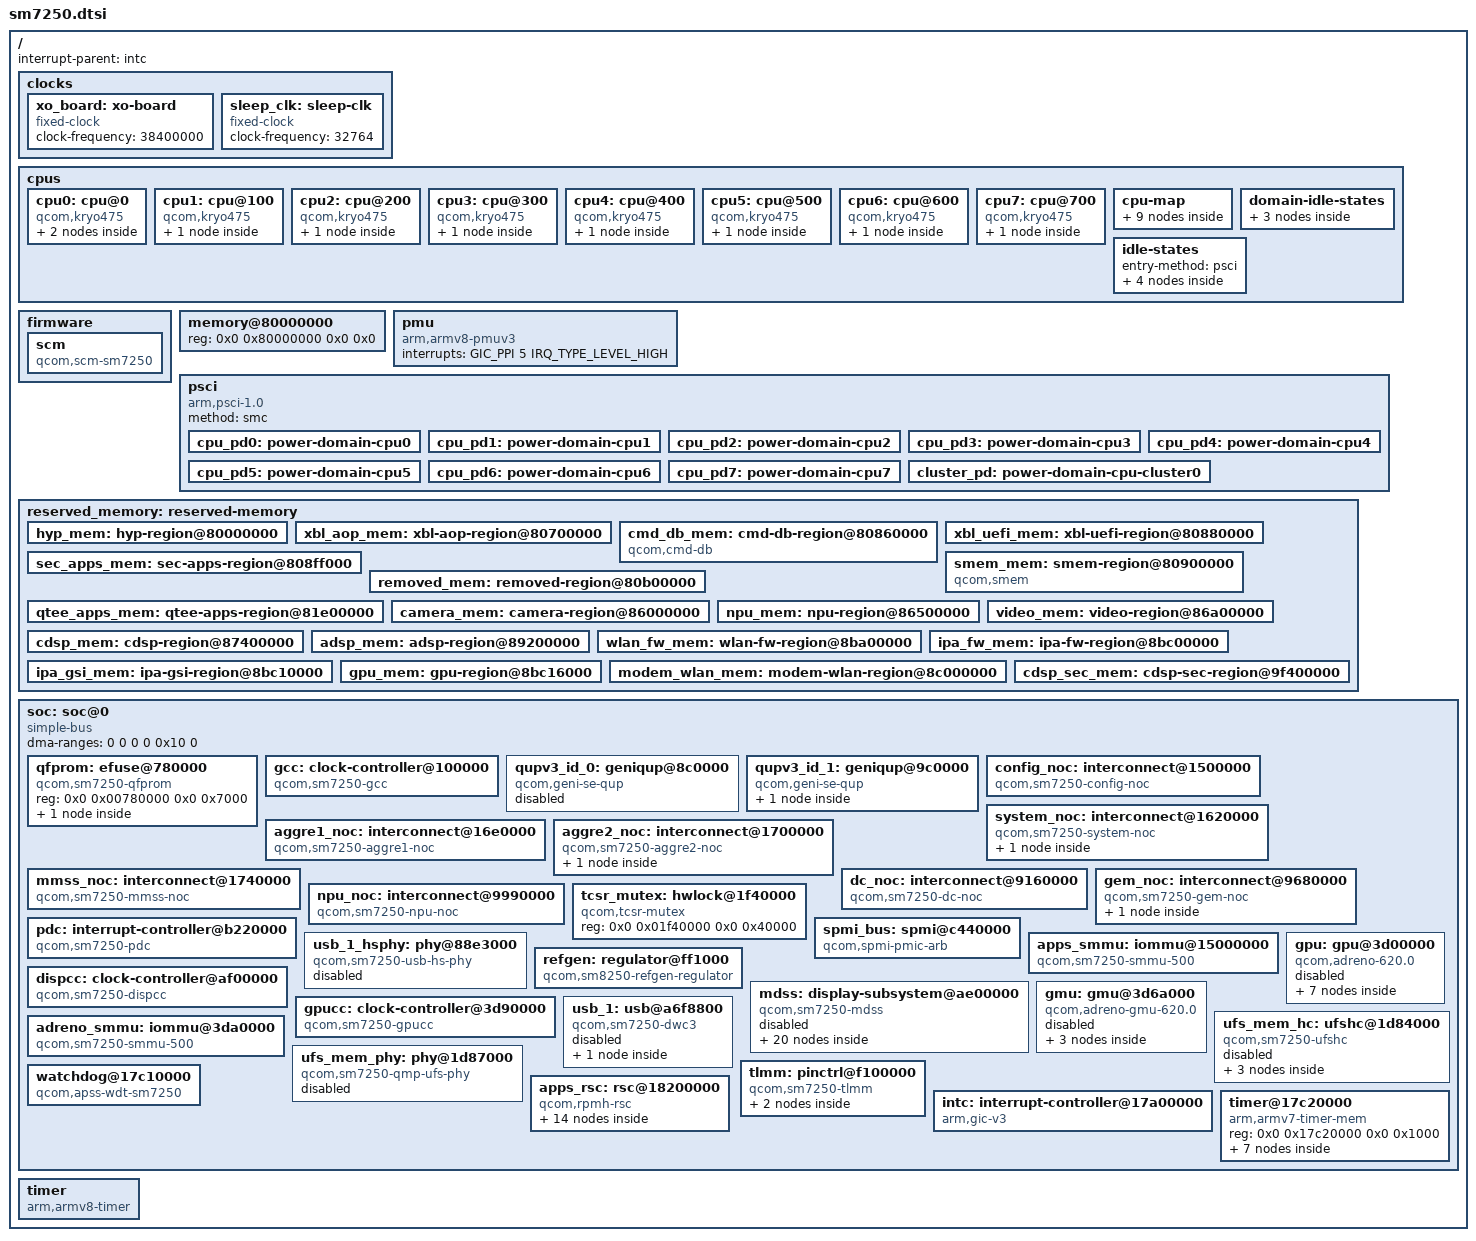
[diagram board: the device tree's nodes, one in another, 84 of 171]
// SPDX-License-Identifier: BSD-3-Clause
/*
 * Copyright (c) 2026, Sreeshankar K <sreeshankar0910@gmail.com>
 *
 * Based on the SM7250 base devicetree posted in the v14 series. The cpufreq
 * and LMH nodes are omitted until their dependencies are in the tree.
 */

#include <dt-bindings/clock/qcom,rpmh.h>
#include <dt-bindings/clock/qcom,sm7250-gcc.h>
#include <dt-bindings/clock/qcom,sm7250-dispcc.h>
#include <dt-bindings/clock/qcom,gpucc-sm7250.h>
#include <dt-bindings/clock/qcom,dsi-phy-28nm.h>
#include <dt-bindings/interconnect/qcom,icc.h>
#include <dt-bindings/interconnect/qcom,sm7250-rpmh.h>
#include <dt-bindings/interrupt-controller/arm-gic.h>
#include <dt-bindings/regulator/qcom,rpmh-regulator.h>
#include <dt-bindings/power/qcom,rpmhpd.h>
#include <dt-bindings/soc/qcom,rpmh-rsc.h>

/ {
	interrupt-parent = <&intc>;
	#address-cells = <2>;
	#size-cells = <2>;

	clocks {
		xo_board: xo-board {
			compatible = "fixed-clock";
			clock-frequency = <38400000>;
			#clock-cells = <0>;
		};

		sleep_clk: sleep-clk {
			compatible = "fixed-clock";
			clock-frequency = <32764>;
			#clock-cells = <0>;
		};
	};

	cpus {
		#address-cells = <2>;
		#size-cells = <0>;

		cpu0: cpu@0 {
			device_type = "cpu";
			compatible = "qcom,kryo475";
			reg = <0x0 0x0>;
			enable-method = "psci";
			capacity-dmips-mhz = <1024>;
			dynamic-power-coefficient = <100>;
			next-level-cache = <&l2_0>;
			power-domains = <&cpu_pd0>;
			power-domain-names = "psci";
			#cooling-cells = <2>;

			l2_0: l2-cache {
				compatible = "cache";
				cache-level = <2>;
				cache-size = <0x20000>;
				cache-unified;
				next-level-cache = <&l3_0>;

				l3_0: l3-cache {
					compatible = "cache";
					cache-level = <3>;
					cache-size = <0x200000>;
					cache-unified;
				};
			};
		};

		cpu1: cpu@100 {
			device_type = "cpu";
			compatible = "qcom,kryo475";
			reg = <0x0 0x100>;
			enable-method = "psci";
			capacity-dmips-mhz = <1024>;
			dynamic-power-coefficient = <100>;
			next-level-cache = <&l2_100>;
			power-domains = <&cpu_pd1>;
			power-domain-names = "psci";
			#cooling-cells = <2>;

			l2_100: l2-cache {
				compatible = "cache";
				cache-level = <2>;
				cache-size = <0x20000>;
				cache-unified;
				next-level-cache = <&l3_0>;
			};
		};

		cpu2: cpu@200 {
			device_type = "cpu";
			compatible = "qcom,kryo475";
			reg = <0x0 0x200>;
			enable-method = "psci";
			capacity-dmips-mhz = <1024>;
			dynamic-power-coefficient = <100>;
			next-level-cache = <&l2_200>;
			power-domains = <&cpu_pd2>;
			power-domain-names = "psci";
			#cooling-cells = <2>;

			l2_200: l2-cache {
				compatible = "cache";
				cache-level = <2>;
				cache-size = <0x20000>;
				cache-unified;
				next-level-cache = <&l3_0>;
			};
		};

		cpu3: cpu@300 {
			device_type = "cpu";
			compatible = "qcom,kryo475";
			reg = <0x0 0x300>;
			enable-method = "psci";
			capacity-dmips-mhz = <1024>;
			dynamic-power-coefficient = <100>;
			next-level-cache = <&l2_300>;
			power-domains = <&cpu_pd3>;
			power-domain-names = "psci";
			#cooling-cells = <2>;

			l2_300: l2-cache {
				compatible = "cache";
				cache-level = <2>;
				cache-size = <0x20000>;
				cache-unified;
				next-level-cache = <&l3_0>;
			};
		};

		cpu4: cpu@400 {
			device_type = "cpu";
			compatible = "qcom,kryo475";
			reg = <0x0 0x400>;
			enable-method = "psci";
			capacity-dmips-mhz = <1024>;
			dynamic-power-coefficient = <100>;
			next-level-cache = <&l2_400>;
			power-domains = <&cpu_pd4>;
			power-domain-names = "psci";
			#cooling-cells = <2>;

			l2_400: l2-cache {
				compatible = "cache";
				cache-level = <2>;
				cache-size = <0x20000>;
				cache-unified;
				next-level-cache = <&l3_0>;
			};
		};

		cpu5: cpu@500 {
			device_type = "cpu";
			compatible = "qcom,kryo475";
			reg = <0x0 0x500>;
			enable-method = "psci";
			capacity-dmips-mhz = <1024>;
			dynamic-power-coefficient = <100>;
			next-level-cache = <&l2_500>;
			power-domains = <&cpu_pd5>;
			power-domain-names = "psci";
			#cooling-cells = <2>;

			l2_500: l2-cache {
				compatible = "cache";
				cache-level = <2>;
				cache-size = <0x20000>;
				cache-unified;
				next-level-cache = <&l3_0>;
			};
		};

		cpu6: cpu@600 {
			device_type = "cpu";
			compatible = "qcom,kryo475";
			reg = <0x0 0x600>;
			enable-method = "psci";
			capacity-dmips-mhz = <1740>;
			dynamic-power-coefficient = <341>;
			next-level-cache = <&l2_600>;
			power-domains = <&cpu_pd6>;
			power-domain-names = "psci";
			#cooling-cells = <2>;

			l2_600: l2-cache {
				compatible = "cache";
				cache-level = <2>;
				cache-size = <0x40000>;
				cache-unified;
				next-level-cache = <&l3_0>;
			};
		};

		cpu7: cpu@700 {
			device_type = "cpu";
			compatible = "qcom,kryo475";
			reg = <0x0 0x700>;
			enable-method = "psci";
			capacity-dmips-mhz = <1740>;
			dynamic-power-coefficient = <375>;
			next-level-cache = <&l2_700>;
			power-domains = <&cpu_pd7>;
			power-domain-names = "psci";
			#cooling-cells = <2>;

			l2_700: l2-cache {
				compatible = "cache";
				cache-level = <2>;
				cache-size = <0x80000>;
				cache-unified;
				next-level-cache = <&l3_0>;
			};
		};

		cpu-map {
			cluster0 {
				core0 {
					cpu = <&cpu0>;
				};

				core1 {
					cpu = <&cpu1>;
				};

				core2 {
					cpu = <&cpu2>;
				};

				core3 {
					cpu = <&cpu3>;
				};

				core4 {
					cpu = <&cpu4>;
				};

				core5 {
					cpu = <&cpu5>;
				};

				core6 {
					cpu = <&cpu6>;
				};

				core7 {
					cpu = <&cpu7>;
				};
			};
		};

		domain-idle-states {
			cluster_sleep_pc: cluster-sleep-0 {
				compatible = "domain-idle-state";
				arm,psci-suspend-param = <0x41000044>;
				entry-latency-us = <2752>;
				exit-latency-us = <3048>;
				min-residency-us = <6118>;
			};

			cluster_sleep_cx: cluster-sleep-1 {
				compatible = "domain-idle-state";
				arm,psci-suspend-param = <0x41002244>;
				entry-latency-us = <3638>;
				exit-latency-us = <4562>;
				min-residency-us = <8467>;
			};

			cluster_sleep_aoss: cluster-sleep-2 {
				compatible = "domain-idle-state";
				arm,psci-suspend-param = <0x4100c244>;
				entry-latency-us = <3263>;
				exit-latency-us = <6562>;
				min-residency-us = <9826>;
			};
		};

		idle-states {
			entry-method = "psci";

			little_cpu_sleep_0: cpu-sleep-0-0 {
				compatible = "arm,idle-state";
				idle-state-name = "little-power-collapse";
				arm,psci-suspend-param = <0x40000003>;
				entry-latency-us = <549>;
				exit-latency-us = <901>;
				min-residency-us = <1774>;
				local-timer-stop;
			};

			little_cpu_sleep_1: cpu-sleep-0-1 {
				compatible = "arm,idle-state";
				idle-state-name = "little-rail-power-collapse";
				arm,psci-suspend-param = <0x40000004>;
				entry-latency-us = <702>;
				exit-latency-us = <915>;
				min-residency-us = <4001>;
				local-timer-stop;
			};

			big_cpu_sleep_0: cpu-sleep-1-0 {
				compatible = "arm,idle-state";
				idle-state-name = "big-power-collapse";
				arm,psci-suspend-param = <0x40000003>;
				entry-latency-us = <523>;
				exit-latency-us = <1244>;
				min-residency-us = <2207>;
				local-timer-stop;
			};

			big_cpu_sleep_1: cpu-sleep-1-1 {
				compatible = "arm,idle-state";
				idle-state-name = "big-rail-power-collapse";
				arm,psci-suspend-param = <0x40000004>;
				entry-latency-us = <526>;
				exit-latency-us = <1854>;
				min-residency-us = <5555>;
				local-timer-stop;
			};
		};
	};

	firmware {
		scm: scm {
			compatible = "qcom,scm-sm7250", "qcom,scm";
			#reset-cells = <1>;
		};
	};

	memory@80000000 {
		device_type = "memory";
		/* We expect the bootloader to fill in the size */
		reg = <0x0 0x80000000 0x0 0x0>;
	};

	pmu {
		compatible = "arm,armv8-pmuv3";
		interrupts = <GIC_PPI 5 IRQ_TYPE_LEVEL_HIGH>;
	};

	psci {
		compatible = "arm,psci-1.0";
		method = "smc";

		cpu_pd0: power-domain-cpu0 {
			#power-domain-cells = <0>;
			power-domains = <&cluster_pd>;
			domain-idle-states = <&little_cpu_sleep_0>,
					     <&little_cpu_sleep_1>;
		};

		cpu_pd1: power-domain-cpu1 {
			#power-domain-cells = <0>;
			power-domains = <&cluster_pd>;
			domain-idle-states = <&little_cpu_sleep_0>,
					     <&little_cpu_sleep_1>;
		};

		cpu_pd2: power-domain-cpu2 {
			#power-domain-cells = <0>;
			power-domains = <&cluster_pd>;
			domain-idle-states = <&little_cpu_sleep_0>,
					     <&little_cpu_sleep_1>;
		};

		cpu_pd3: power-domain-cpu3 {
			#power-domain-cells = <0>;
			power-domains = <&cluster_pd>;
			domain-idle-states = <&little_cpu_sleep_0>,
					     <&little_cpu_sleep_1>;
		};

		cpu_pd4: power-domain-cpu4 {
			#power-domain-cells = <0>;
			power-domains = <&cluster_pd>;
			domain-idle-states = <&little_cpu_sleep_0>,
					     <&little_cpu_sleep_1>;
		};

		cpu_pd5: power-domain-cpu5 {
			#power-domain-cells = <0>;
			power-domains = <&cluster_pd>;
			domain-idle-states = <&little_cpu_sleep_0>,
					     <&little_cpu_sleep_1>;
		};

		cpu_pd6: power-domain-cpu6 {
			#power-domain-cells = <0>;
			power-domains = <&cluster_pd>;
			domain-idle-states = <&big_cpu_sleep_0>,
					     <&big_cpu_sleep_1>;
		};

		cpu_pd7: power-domain-cpu7 {
			#power-domain-cells = <0>;
			power-domains = <&cluster_pd>;
			domain-idle-states = <&big_cpu_sleep_0>,
					     <&big_cpu_sleep_1>;
		};

		cluster_pd: power-domain-cpu-cluster0 {
			#power-domain-cells = <0>;
			domain-idle-states = <&cluster_sleep_pc>,
					     <&cluster_sleep_cx>,
					     <&cluster_sleep_aoss>;
		};
	};

	reserved_memory: reserved-memory {
		#address-cells = <2>;
		#size-cells = <2>;
		ranges;

		hyp_mem: hyp-region@80000000 {
			reg = <0x0 0x80000000 0x0 0x600000>;
			no-map;
		};

		xbl_aop_mem: xbl-aop-region@80700000 {
			reg = <0x0 0x80700000 0x0 0x160000>;
			no-map;
		};

		cmd_db_mem: cmd-db-region@80860000 {
			compatible = "qcom,cmd-db";
			reg = <0x0 0x80860000 0x0 0x20000>;
			no-map;
		};

		xbl_uefi_mem: xbl-uefi-region@80880000 {
			reg = <0x0 0x80880000 0x0 0x14000>;
			no-map;
		};

		sec_apps_mem: sec-apps-region@808ff000 {
			reg = <0x0 0x808ff000 0x0 0x1000>;
			no-map;
		};

		smem_mem: smem-region@80900000 {
			compatible = "qcom,smem";
			reg = <0x0 0x80900000 0x0 0x200000>;
			no-map;
			hwlocks = <&tcsr_mutex 3>;
		};

		removed_mem: removed-region@80b00000 {
			reg = <0x0 0x80b00000 0x0 0x1300000>;
			no-map;
		};

		qtee_apps_mem: qtee-apps-region@81e00000 {
			reg = <0x0 0x81e00000 0x0 0x2600000>;
			no-map;
		};

		camera_mem: camera-region@86000000 {
			reg = <0x0 0x86000000 0x0 0x500000>;
			no-map;
		};

		npu_mem: npu-region@86500000 {
			reg = <0x0 0x86500000 0x0 0x500000>;
			no-map;
		};

		video_mem: video-region@86a00000 {
			reg = <0x0 0x86a00000 0x0 0x500000>;
			no-map;
		};

		cdsp_mem: cdsp-region@87400000 {
			reg = <0x0 0x87400000 0x0 0x1e00000>;
			no-map;
		};

		adsp_mem: adsp-region@89200000 {
			reg = <0x0 0x89200000 0x0 0x2800000>;
			no-map;
		};

		wlan_fw_mem: wlan-fw-region@8ba00000 {
			reg = <0x0 0x8ba00000 0x0 0x200000>;
			no-map;
		};

		ipa_fw_mem: ipa-fw-region@8bc00000 {
			reg = <0x0 0x8bc00000 0x0 0x10000>;
			no-map;
		};

		ipa_gsi_mem: ipa-gsi-region@8bc10000 {
			reg = <0x0 0x8bc10000 0x0 0x6000>;
			no-map;
		};

		gpu_mem: gpu-region@8bc16000 {
			reg = <0x0 0x8bc16000 0x0 0x2000>;
			no-map;
		};

		modem_wlan_mem: modem-wlan-region@8c000000 {
			reg = <0x0 0x8c000000 0x0 0xf800000>;
			no-map;
		};

		cdsp_sec_mem: cdsp-sec-region@9f400000 {
			reg = <0x0 0x9f400000 0x0 0xc00000>;
			no-map;
		};
	};

	soc: soc@0 {
		compatible = "simple-bus";
		#address-cells = <2>;
		#size-cells = <2>;
		ranges = <0 0 0 0 0x10 0>;
		dma-ranges = <0 0 0 0 0x10 0>;

		qfprom: efuse@780000 {
			compatible = "qcom,sm7250-qfprom", "qcom,qfprom";
			reg = <0x0 0x00780000 0x0 0x7000>;
			#address-cells = <1>;
			#size-cells = <1>;

			gpu_speed_bin: gpu-speed-bin@1ea {
				reg = <0x1ea 0x2>;
				bits = <5 8>;
			};
		};

		gcc: clock-controller@100000 {
			compatible = "qcom,sm7250-gcc";
			reg = <0x0 0x00100000 0x0 0x1f0000>;
			clocks = <&rpmhcc RPMH_CXO_CLK>,
				 <&rpmhcc RPMH_CXO_CLK_A>,
				 <&sleep_clk>;
			#clock-cells = <1>;
			#reset-cells = <1>;
			#power-domain-cells = <1>;
		};

		qupv3_id_0: geniqup@8c0000 {
			compatible = "qcom,geni-se-qup";
			reg = <0x0 0x008c0000 0x0 0x6000>;
			clock-names = "m-ahb", "s-ahb";
			clocks = <&gcc GCC_QUPV3_WRAP_0_M_AHB_CLK>,
				 <&gcc GCC_QUPV3_WRAP_0_S_AHB_CLK>;
			#address-cells = <2>;
			#size-cells = <2>;
			ranges;
			status = "disabled";
		};

		qupv3_id_1: geniqup@9c0000 {
			compatible = "qcom,geni-se-qup";
			reg = <0x0 0x009c0000 0x0 0x6000>;
			clock-names = "m-ahb", "s-ahb";
			clocks = <&gcc GCC_QUPV3_WRAP_1_M_AHB_CLK>,
				 <&gcc GCC_QUPV3_WRAP_1_S_AHB_CLK>;
			#address-cells = <2>;
			#size-cells = <2>;
			ranges;

			uart2: serial@988000 {
				compatible = "qcom,geni-debug-uart";
				reg = <0 0x00988000 0 0x4000>;
				clock-names = "se";
				clocks = <&gcc GCC_QUPV3_WRAP1_S2_CLK>;
				interrupts = <GIC_SPI 355 IRQ_TYPE_LEVEL_HIGH>;
				status = "disabled";
			};
		};

		config_noc: interconnect@1500000 {
			compatible = "qcom,sm7250-config-noc";
			reg = <0x0 0x01500000 0x0 0x28000>;
			#interconnect-cells = <2>;
			qcom,bcm-voters = <&apps_bcm_voter>;
		};

		system_noc: interconnect@1620000 {
			compatible = "qcom,sm7250-system-noc";
			reg = <0x0 0x01620000 0x0 0x19200>;
			#interconnect-cells = <2>;
			qcom,bcm-voters = <&apps_bcm_voter>;

			qup_virt: interconnect-qup-virt {
				compatible = "qcom,sm7250-qup-virt";
				#interconnect-cells = <2>;
				qcom,bcm-voters = <&apps_bcm_voter>;
			};
		};

		aggre1_noc: interconnect@16e0000 {
			compatible = "qcom,sm7250-aggre1-noc";
			reg = <0x0 0x016e0000 0x0 0x15080>;
			#interconnect-cells = <2>;
			qcom,bcm-voters = <&apps_bcm_voter>;
		};

		aggre2_noc: interconnect@1700000 {
			compatible = "qcom,sm7250-aggre2-noc";
			reg = <0x0 0x01700000 0x0 0x23080>;
			#interconnect-cells = <2>;
			qcom,bcm-voters = <&apps_bcm_voter>;

			compute_noc: interconnect-compute-noc {
				compatible = "qcom,sm7250-compute-noc";
				#interconnect-cells = <2>;
				qcom,bcm-voters = <&apps_bcm_voter>;
			};
		};

		mmss_noc: interconnect@1740000 {
			compatible = "qcom,sm7250-mmss-noc";
			reg = <0x0 0x01740000 0x0 0x1c100>;
			#interconnect-cells = <2>;
			qcom,bcm-voters = <&apps_bcm_voter>;
		};

		dc_noc: interconnect@9160000 {
			compatible = "qcom,sm7250-dc-noc";
			reg = <0x0 0x09160000 0x0 0x3200>;
			#interconnect-cells = <2>;
			qcom,bcm-voters = <&apps_bcm_voter>;
		};

		gem_noc: interconnect@9680000 {
			compatible = "qcom,sm7250-gem-noc";
			reg = <0x0 0x09680000 0x0 0x3e200>;
			#interconnect-cells = <2>;
			qcom,bcm-voters = <&apps_bcm_voter>;

			mc_virt: interconnect-mc-virt {
				compatible = "qcom,sm7250-mc-virt";
				#interconnect-cells = <2>;
				qcom,bcm-voters = <&apps_bcm_voter>;
			};
		};

		npu_noc: interconnect@9990000 {
			compatible = "qcom,sm7250-npu-noc";
			reg = <0x0 0x09990000 0x0 0x1600>;
			#interconnect-cells = <2>;
			qcom,bcm-voters = <&apps_bcm_voter>;
		};

		tcsr_mutex: hwlock@1f40000 {
			compatible = "qcom,tcsr-mutex";
			reg = <0x0 0x01f40000 0x0 0x40000>;
			#hwlock-cells = <1>;
		};

		pdc: interrupt-controller@b220000 {
			compatible = "qcom,sm7250-pdc", "qcom,pdc";
			reg = <0 0xb220000 0 0x30000>, <0 0x17c000f0 0 0x60>;
			qcom,pdc-ranges = <0 480 42>,
					  <42 612 28>,
					  <70 63 1>,
					  <71 640 15>,
					  <86 522 52>;
			#interrupt-cells = <2>;
			interrupt-parent = <&intc>;
			interrupt-controller;
		};

		spmi_bus: spmi@c440000 {
			compatible = "qcom,spmi-pmic-arb";
			reg = <0x0 0x0c440000 0x0 0x0001100>,
			      <0x0 0x0c600000 0x0 0x2000000>,
			      <0x0 0x0e600000 0x0 0x0100000>,
			      <0x0 0x0e700000 0x0 0x00a0000>,
			      <0x0 0x0c40a000 0x0 0x0026000>;
			reg-names = "core",
				    "chnls",
				    "obsrvr",
				    "intr",
				    "cnfg";
			interrupt-names = "periph_irq";
			interrupts-extended = <&pdc 1 IRQ_TYPE_LEVEL_HIGH>;
			qcom,ee = <0>;
			qcom,channel = <0>;
			#address-cells = <2>;
			#size-cells = <0>;
			interrupt-controller;
			#interrupt-cells = <4>;
		};

		usb_1_hsphy: phy@88e3000 {
			compatible = "qcom,sm7250-usb-hs-phy",
				     "qcom,usb-snps-hs-7nm-phy";
			reg = <0x0 0x088e3000 0x0 0x400>;
			status = "disabled";
			#phy-cells = <0>;

			clocks = <&rpmhcc RPMH_CXO_CLK>;
			clock-names = "ref";

			resets = <&gcc GCC_QUSB2PHY_PRIM_BCR>;
		};

		apps_smmu: iommu@15000000 {
			compatible = "qcom,sm7250-smmu-500", "qcom,smmu-500", "arm,mmu-500";
			reg = <0x0 0x15000000 0x0 0x100000>;
			#iommu-cells = <2>;
			#global-interrupts = <1>;

			interrupts =
				<GIC_SPI 65 IRQ_TYPE_LEVEL_HIGH>,
				<GIC_SPI 97 IRQ_TYPE_LEVEL_HIGH>,
				<GIC_SPI 98 IRQ_TYPE_LEVEL_HIGH>,
				<GIC_SPI 99 IRQ_TYPE_LEVEL_HIGH>,
				<GIC_SPI 100 IRQ_TYPE_LEVEL_HIGH>,
				<GIC_SPI 101 IRQ_TYPE_LEVEL_HIGH>,
				<GIC_SPI 102 IRQ_TYPE_LEVEL_HIGH>,
				<GIC_SPI 103 IRQ_TYPE_LEVEL_HIGH>,
				<GIC_SPI 104 IRQ_TYPE_LEVEL_HIGH>,
				<GIC_SPI 105 IRQ_TYPE_LEVEL_HIGH>,
				<GIC_SPI 106 IRQ_TYPE_LEVEL_HIGH>,
				<GIC_SPI 107 IRQ_TYPE_LEVEL_HIGH>,
				<GIC_SPI 108 IRQ_TYPE_LEVEL_HIGH>,
				<GIC_SPI 109 IRQ_TYPE_LEVEL_HIGH>,
				<GIC_SPI 110 IRQ_TYPE_LEVEL_HIGH>,
				<GIC_SPI 111 IRQ_TYPE_LEVEL_HIGH>,
				<GIC_SPI 112 IRQ_TYPE_LEVEL_HIGH>,
				<GIC_SPI 113 IRQ_TYPE_LEVEL_HIGH>,
				<GIC_SPI 114 IRQ_TYPE_LEVEL_HIGH>,
				<GIC_SPI 115 IRQ_TYPE_LEVEL_HIGH>,
				<GIC_SPI 116 IRQ_TYPE_LEVEL_HIGH>,
				<GIC_SPI 117 IRQ_TYPE_LEVEL_HIGH>,
				<GIC_SPI 118 IRQ_TYPE_LEVEL_HIGH>,
				<GIC_SPI 181 IRQ_TYPE_LEVEL_HIGH>,
				<GIC_SPI 182 IRQ_TYPE_LEVEL_HIGH>,
				<GIC_SPI 183 IRQ_TYPE_LEVEL_HIGH>,
				<GIC_SPI 184 IRQ_TYPE_LEVEL_HIGH>,
				<GIC_SPI 179 IRQ_TYPE_LEVEL_HIGH>,
				<GIC_SPI 186 IRQ_TYPE_LEVEL_HIGH>,
				<GIC_SPI 187 IRQ_TYPE_LEVEL_HIGH>,
				<GIC_SPI 188 IRQ_TYPE_LEVEL_HIGH>,
				<GIC_SPI 189 IRQ_TYPE_LEVEL_HIGH>,
				<GIC_SPI 190 IRQ_TYPE_LEVEL_HIGH>,
				<GIC_SPI 191 IRQ_TYPE_LEVEL_HIGH>,
				<GIC_SPI 192 IRQ_TYPE_LEVEL_HIGH>,
				<GIC_SPI 315 IRQ_TYPE_LEVEL_HIGH>,
				<GIC_SPI 316 IRQ_TYPE_LEVEL_HIGH>,
				<GIC_SPI 317 IRQ_TYPE_LEVEL_HIGH>,
				<GIC_SPI 318 IRQ_TYPE_LEVEL_HIGH>,
				<GIC_SPI 319 IRQ_TYPE_LEVEL_HIGH>,
				<GIC_SPI 320 IRQ_TYPE_LEVEL_HIGH>,
				<GIC_SPI 321 IRQ_TYPE_LEVEL_HIGH>,
				<GIC_SPI 322 IRQ_TYPE_LEVEL_HIGH>,
				<GIC_SPI 323 IRQ_TYPE_LEVEL_HIGH>,
				<GIC_SPI 324 IRQ_TYPE_LEVEL_HIGH>,
				<GIC_SPI 325 IRQ_TYPE_LEVEL_HIGH>,
				<GIC_SPI 326 IRQ_TYPE_LEVEL_HIGH>,
				<GIC_SPI 327 IRQ_TYPE_LEVEL_HIGH>,
				<GIC_SPI 328 IRQ_TYPE_LEVEL_HIGH>,
				<GIC_SPI 329 IRQ_TYPE_LEVEL_HIGH>,
				<GIC_SPI 330 IRQ_TYPE_LEVEL_HIGH>,
				<GIC_SPI 331 IRQ_TYPE_LEVEL_HIGH>,
				<GIC_SPI 332 IRQ_TYPE_LEVEL_HIGH>,
				<GIC_SPI 333 IRQ_TYPE_LEVEL_HIGH>,
				<GIC_SPI 334 IRQ_TYPE_LEVEL_HIGH>,
				<GIC_SPI 335 IRQ_TYPE_LEVEL_HIGH>,
				<GIC_SPI 336 IRQ_TYPE_LEVEL_HIGH>,
				<GIC_SPI 337 IRQ_TYPE_LEVEL_HIGH>,
				<GIC_SPI 338 IRQ_TYPE_LEVEL_HIGH>,
				<GIC_SPI 339 IRQ_TYPE_LEVEL_HIGH>,
				<GIC_SPI 340 IRQ_TYPE_LEVEL_HIGH>,
				<GIC_SPI 341 IRQ_TYPE_LEVEL_HIGH>,
				<GIC_SPI 342 IRQ_TYPE_LEVEL_HIGH>,
				<GIC_SPI 343 IRQ_TYPE_LEVEL_HIGH>,
				<GIC_SPI 344 IRQ_TYPE_LEVEL_HIGH>,
				<GIC_SPI 345 IRQ_TYPE_LEVEL_HIGH>,
				<GIC_SPI 395 IRQ_TYPE_LEVEL_HIGH>,
				<GIC_SPI 396 IRQ_TYPE_LEVEL_HIGH>,
				<GIC_SPI 397 IRQ_TYPE_LEVEL_HIGH>,
				<GIC_SPI 398 IRQ_TYPE_LEVEL_HIGH>,
				<GIC_SPI 399 IRQ_TYPE_LEVEL_HIGH>,
				<GIC_SPI 400 IRQ_TYPE_LEVEL_HIGH>,
				<GIC_SPI 401 IRQ_TYPE_LEVEL_HIGH>,
				<GIC_SPI 402 IRQ_TYPE_LEVEL_HIGH>,
				<GIC_SPI 403 IRQ_TYPE_LEVEL_HIGH>,
				<GIC_SPI 404 IRQ_TYPE_LEVEL_HIGH>,
				<GIC_SPI 405 IRQ_TYPE_LEVEL_HIGH>,
				<GIC_SPI 406 IRQ_TYPE_LEVEL_HIGH>,
				<GIC_SPI 407 IRQ_TYPE_LEVEL_HIGH>,
				<GIC_SPI 408 IRQ_TYPE_LEVEL_HIGH>,
				<GIC_SPI 409 IRQ_TYPE_LEVEL_HIGH>;
		};

		refgen: regulator@ff1000 {
			compatible = "qcom,sm8250-refgen-regulator";
			reg = <0x0 0x00ff1000 0x0 0x84>;
			regulator-always-on;
		};

		mdss: display-subsystem@ae00000 {
			compatible = "qcom,sm7250-mdss";
			reg = <0x0 0x0ae00000 0x0 0x1000>;
			reg-names = "mdss";

			interconnects = <&mmss_noc MASTER_MDP_PORT0 QCOM_ICC_TAG_ALWAYS
					 &mc_virt SLAVE_EBI_CH0 QCOM_ICC_TAG_ALWAYS>,
					<&mmss_noc MASTER_MDP_PORT1 QCOM_ICC_TAG_ALWAYS
					 &mc_virt SLAVE_EBI_CH0 QCOM_ICC_TAG_ALWAYS>,
					<&gem_noc MASTER_AMPSS_M0 QCOM_ICC_TAG_ACTIVE_ONLY
					 &config_noc SLAVE_DISPLAY_CFG QCOM_ICC_TAG_ACTIVE_ONLY>;
			interconnect-names = "mdp0-mem", "mdp1-mem", "cpu-cfg";

			power-domains = <&dispcc MDSS_GDSC>;

			clocks = <&dispcc DISPCC_MDSS_AHB_CLK>,
				 <&gcc GCC_DISP_HF_AXI_CLK>,
				 <&gcc GCC_DISP_SF_AXI_CLK>,
				 <&dispcc DISPCC_MDSS_MDP_CLK>;
			clock-names = "iface", "bus", "nrt_bus", "core";

			interrupts = <GIC_SPI 83 IRQ_TYPE_LEVEL_HIGH>;
			interrupt-controller;
			#interrupt-cells = <1>;

			/* downstream smmu_sde_unsec: iommus = <&apps_smmu 0xb40 0x402> */
			iommus = <&apps_smmu 0xb40 0x402>;

			/*
			 * The bootloader leaves the DPU scanning the splash
			 * framebuffer through the SMMU with iova == phys.
			 * Keep it identity mapped from the moment the SMMU
			 * attaches the device, otherwise SIDs 0xb40/0xf40
			 * take context faults until msm takes over.
			 */
			memory-region = <&cont_splash_mem>;

			resets = <&dispcc DISPCC_MDSS_CORE_BCR>;

			status = "disabled";

			#address-cells = <2>;
			#size-cells = <2>;
			ranges;

			mdss_mdp: display-controller@ae01000 {
				compatible = "qcom,sm7250-dpu";
				reg = <0x0 0x0ae01000 0x0 0x83208>,
				      <0x0 0x0aeb0000 0x0 0x2008>;
				reg-names = "mdp", "vbif";

				clocks = <&dispcc DISPCC_MDSS_AHB_CLK>,
					 <&gcc GCC_DISP_HF_AXI_CLK>,
					 <&dispcc DISPCC_MDSS_MDP_CLK>,
					 <&dispcc DISPCC_MDSS_VSYNC_CLK>;
				clock-names = "iface", "bus", "core", "vsync";

				assigned-clocks = <&dispcc DISPCC_MDSS_VSYNC_CLK>;
				assigned-clock-rates = <19200000>;

				operating-points-v2 = <&mdp_opp_table>;
				power-domains = <&rpmhpd RPMHPD_CX>;

				interrupt-parent = <&mdss>;
				interrupts = <0>;

				ports {
					#address-cells = <1>;
					#size-cells = <0>;

					port@0 {
						reg = <0>;
						dpu_intf1_out: endpoint {
							remote-endpoint = <&mdss_dsi0_in>;
						};
					};
				};

				/* Downstream clock vdd levels of disp_cc_mdss_mdp_clk_src */
				mdp_opp_table: opp-table {
					compatible = "operating-points-v2";

					opp-200000000 {
						opp-hz = /bits/ 64 <200000000>;
						required-opps = <&rpmhpd_opp_low_svs>;
					};

					opp-300000000 {
						opp-hz = /bits/ 64 <300000000>;
						required-opps = <&rpmhpd_opp_svs>;
					};

					opp-345000000 {
						opp-hz = /bits/ 64 <345000000>;
						required-opps = <&rpmhpd_opp_svs_l1>;
					};

					opp-460000000 {
						opp-hz = /bits/ 64 <460000000>;
						required-opps = <&rpmhpd_opp_nom>;
					};
				};
			};

			mdss_dsi0: dsi@ae94000 {
				compatible = "qcom,sm7250-dsi-ctrl",
					     "qcom,mdss-dsi-ctrl";
				reg = <0x0 0x0ae94000 0x0 0x400>;
				reg-names = "dsi_ctrl";

				interrupt-parent = <&mdss>;
				interrupts = <4>;

				clocks = <&dispcc DISPCC_MDSS_BYTE0_CLK>,
					 <&dispcc DISPCC_MDSS_BYTE0_INTF_CLK>,
					 <&dispcc DISPCC_MDSS_PCLK0_CLK>,
					 <&dispcc DISPCC_MDSS_ESC0_CLK>,
					 <&dispcc DISPCC_MDSS_AHB_CLK>,
					 <&gcc GCC_DISP_HF_AXI_CLK>;
				clock-names = "byte",
					      "byte_intf",
					      "pixel",
					      "core",
					      "iface",
					      "bus";

				assigned-clocks = <&dispcc DISPCC_MDSS_BYTE0_CLK_SRC>,
						  <&dispcc DISPCC_MDSS_PCLK0_CLK_SRC>;
				assigned-clock-parents = <&mdss_dsi0_phy DSI_BYTE_PLL_CLK>,
							 <&mdss_dsi0_phy DSI_PIXEL_PLL_CLK>;

				operating-points-v2 = <&dsi_opp_table>;
				power-domains = <&rpmhpd RPMHPD_CX>;

				phys = <&mdss_dsi0_phy>;

				refgen-supply = <&refgen>;

				status = "disabled";

				#address-cells = <1>;
				#size-cells = <0>;

				ports {
					#address-cells = <1>;
					#size-cells = <0>;

					port@0 {
						reg = <0>;
						mdss_dsi0_in: endpoint {
							remote-endpoint = <&dpu_intf1_out>;
						};
					};

					port@1 {
						reg = <1>;
						mdss_dsi0_out: endpoint {
						};
					};
				};

				/* Downstream clock vdd levels of disp_cc_mdss_byte0_clk_src */
				dsi_opp_table: opp-table {
					compatible = "operating-points-v2";

					opp-187500000 {
						opp-hz = /bits/ 64 <187500000>;
						required-opps = <&rpmhpd_opp_low_svs>;
					};

					opp-300000000 {
						opp-hz = /bits/ 64 <300000000>;
						required-opps = <&rpmhpd_opp_svs>;
					};

					opp-358000000 {
						opp-hz = /bits/ 64 <358000000>;
						required-opps = <&rpmhpd_opp_svs_l1>;
					};
				};
			};

			/* Downstream "qcom,dsi-phy-v4.1", 7nm, same as sm8250 */
			mdss_dsi0_phy: phy@ae94400 {
				compatible = "qcom,dsi-phy-7nm";
				reg = <0x0 0x0ae94400 0x0 0x200>,
				      <0x0 0x0ae94600 0x0 0x280>,
				      <0x0 0x0ae94900 0x0 0x260>;
				reg-names = "dsi_phy",
					    "dsi_phy_lane",
					    "dsi_pll";

				#clock-cells = <1>;
				#phy-cells = <0>;

				clocks = <&dispcc DISPCC_MDSS_AHB_CLK>,
					 <&rpmhcc RPMH_CXO_CLK>;
				clock-names = "iface", "ref";

				status = "disabled";
			};
		};
		dispcc: clock-controller@af00000 {
			compatible = "qcom,sm7250-dispcc";
			reg = <0x0 0x0af00000 0x0 0x20000>;
			clocks = <&rpmhcc RPMH_CXO_CLK>,
				 <&rpmhcc RPMH_CXO_CLK_A>,
				 <&gcc GCC_DISP_GPLL0_CLK_SRC>,
				 <&sleep_clk>,
				 <&mdss_dsi0_phy DSI_BYTE_PLL_CLK>,
				 <&mdss_dsi0_phy DSI_PIXEL_PLL_CLK>,
				 <0>,
				 <0>,
				 <0>,
				 <0>;
			power-domains = <&rpmhpd RPMHPD_CX>;
			required-opps = <&rpmhpd_opp_low_svs>;
			#clock-cells = <1>;
			#reset-cells = <1>;
			#power-domain-cells = <1>;
		};

		gpu: gpu@3d00000 {
			compatible = "qcom,adreno-620.0", "qcom,adreno";
			reg = <0x0 0x03d00000 0x0 0x40000>;
			reg-names = "kgsl_3d0_reg_memory";

			interrupts = <GIC_SPI 300 IRQ_TYPE_LEVEL_HIGH>;

			iommus = <&adreno_smmu 0 0x401>;

			operating-points-v2 = <&gpu_opp_table>;

			nvmem-cells = <&gpu_speed_bin>;
			nvmem-cell-names = "speed_bin";

			qcom,gmu = <&gmu>;

			interconnects = <&gem_noc MASTER_GRAPHICS_3D QCOM_ICC_TAG_ALWAYS
					 &mc_virt SLAVE_EBI_CH0 QCOM_ICC_TAG_ALWAYS>;
			interconnect-names = "gfx-mem";

			#cooling-cells = <2>;

			status = "disabled";

			zap-shader {
				memory-region = <&gpu_mem>;
			};

			gpu_opp_table: opp-table {
				compatible = "operating-points-v2";

				opp-625000000 {
					opp-hz = /bits/ 64 <625000000>;
					opp-peak-kBps = <6220000>;
					opp-level = <RPMH_REGULATOR_LEVEL_NOM>;
					opp-supported-hw = <0x03>;
				};

				opp-540000000 {
					opp-hz = /bits/ 64 <540000000>;
					opp-level = <RPMH_REGULATOR_LEVEL_SVS_L1>;
					opp-supported-hw = <0x08>;
				};

				opp-500000000 {
					opp-hz = /bits/ 64 <500000000>;
					opp-peak-kBps = <4068000>;
					opp-level = <RPMH_REGULATOR_LEVEL_SVS_L1>;
					opp-supported-hw = <0x03>;
				};

				opp-400000000 {
					opp-hz = /bits/ 64 <400000000>;
					opp-peak-kBps = <3072000>;
					opp-level = <RPMH_REGULATOR_LEVEL_SVS>;
					opp-supported-hw = <0x0b>;
				};

				opp-275000000 {
					opp-hz = /bits/ 64 <275000000>;
					opp-peak-kBps = <2188000>;
					opp-level = <RPMH_REGULATOR_LEVEL_LOW_SVS>;
					opp-supported-hw = <0x0b>;
				};
			};
		};
		gmu: gmu@3d6a000 {
			compatible = "qcom,adreno-gmu-620.0", "qcom,adreno-gmu";
			reg = <0x0 0x03d6a000 0x0 0x30000>,
			      <0x0 0x03de0000 0x0 0x10000>,
			      <0x0 0x0b290000 0x0 0x10000>,
			      <0x0 0x0b490000 0x0 0x10000>;
			reg-names = "gmu", "rscc", "gmu_pdc", "gmu_pdc_seq";

			interrupts = <GIC_SPI 304 IRQ_TYPE_LEVEL_HIGH>,
				     <GIC_SPI 305 IRQ_TYPE_LEVEL_HIGH>;
			interrupt-names = "hfi", "gmu";

			clocks = <&gpucc GPU_CC_AHB_CLK>,
				 <&gpucc GPU_CC_CX_GMU_CLK>,
				 <&gpucc GPU_CC_CXO_CLK>,
				 <&gcc GCC_DDRSS_GPU_AXI_CLK>,
				 <&gcc GCC_GPU_MEMNOC_GFX_CLK>;
			clock-names = "ahb", "gmu", "cxo", "axi", "memnoc";

			power-domains = <&gpucc GPU_CX_GDSC>,
					<&gpucc GPU_GX_GDSC>;
			power-domain-names = "cx", "gx";

			iommus = <&adreno_smmu 5 0x400>;

			operating-points-v2 = <&gmu_opp_table>;

			status = "disabled";

			gmu_opp_table: opp-table {
				compatible = "operating-points-v2";

				opp-200000000 {
					opp-hz = /bits/ 64 <200000000>;
					opp-level = <RPMH_REGULATOR_LEVEL_LOW_SVS>;
				};

				opp-500000000 {
					opp-hz = /bits/ 64 <500000000>;
					opp-level = <RPMH_REGULATOR_LEVEL_SVS>;
				};
			};
		};
		gpucc: clock-controller@3d90000 {
			compatible = "qcom,sm7250-gpucc";
			reg = <0x0 0x03d90000 0x0 0x9000>;
			clocks = <&rpmhcc RPMH_CXO_CLK>,
				 <&gcc GCC_GPU_GPLL0_CLK_SRC>,
				 <&gcc GCC_GPU_GPLL0_DIV_CLK_SRC>;
			clock-names = "bi_tcxo",
				      "gcc_gpu_gpll0_clk_src",
				      "gcc_gpu_gpll0_div_clk_src";
			#clock-cells = <1>;
			#reset-cells = <1>;
			#power-domain-cells = <1>;
		};
		adreno_smmu: iommu@3da0000 {
			compatible = "qcom,sm7250-smmu-500", "qcom,adreno-smmu",
				     "qcom,smmu-500", "arm,mmu-500";
			reg = <0x0 0x03da0000 0x0 0x10000>;
			#iommu-cells = <2>;
			#global-interrupts = <1>;
			interrupts = <GIC_SPI 673 IRQ_TYPE_LEVEL_HIGH>,
				     <GIC_SPI 678 IRQ_TYPE_LEVEL_HIGH>,
				     <GIC_SPI 679 IRQ_TYPE_LEVEL_HIGH>,
				     <GIC_SPI 680 IRQ_TYPE_LEVEL_HIGH>,
				     <GIC_SPI 681 IRQ_TYPE_LEVEL_HIGH>,
				     <GIC_SPI 682 IRQ_TYPE_LEVEL_HIGH>,
				     <GIC_SPI 683 IRQ_TYPE_LEVEL_HIGH>,
				     <GIC_SPI 684 IRQ_TYPE_LEVEL_HIGH>,
				     <GIC_SPI 685 IRQ_TYPE_LEVEL_HIGH>;
			clocks = <&gpucc GPU_CC_AHB_CLK>,
				 <&gcc GCC_GPU_MEMNOC_GFX_CLK>,
				 <&gcc GCC_GPU_SNOC_DVM_GFX_CLK>;
			clock-names = "ahb", "bus", "iface";

			power-domains = <&gpucc GPU_CX_GDSC>;
			dma-coherent;
		};

		usb_1: usb@a6f8800 {
			compatible = "qcom,sm7250-dwc3", "qcom,dwc3";
			reg = <0x0 0x0a6f8800 0x0 0x400>;
			status = "disabled";
			#address-cells = <2>;
			#size-cells = <2>;
			ranges;

			clocks = <&gcc GCC_CFG_NOC_USB3_PRIM_AXI_CLK>,
				 <&gcc GCC_USB30_PRIM_MASTER_CLK>,
				 <&gcc GCC_AGGRE_USB3_PRIM_AXI_CLK>,
				 <&gcc GCC_USB30_PRIM_SLEEP_CLK>,
				 <&gcc GCC_USB30_PRIM_MOCK_UTMI_CLK>,
				 <&gcc GCC_USB3_PRIM_CLKREF_CLK>;
			clock-names = "cfg_noc", "core", "iface", "sleep",
				      "mock_utmi", "xo";

			assigned-clocks = <&gcc GCC_USB30_PRIM_MOCK_UTMI_CLK>,
					  <&gcc GCC_USB30_PRIM_MASTER_CLK>;
			assigned-clock-rates = <19200000>, <66666667>;

			interrupts-extended = <&intc GIC_SPI 144 IRQ_TYPE_LEVEL_HIGH>,
					      <&pdc 14 IRQ_TYPE_EDGE_BOTH>,
					      <&pdc 15 IRQ_TYPE_EDGE_BOTH>,
					      <&pdc 9 IRQ_TYPE_LEVEL_HIGH>;
			interrupt-names = "pwr_event", "dp_hs_phy_irq",
					  "dm_hs_phy_irq", "ss_phy_irq";

			power-domains = <&gcc USB30_PRIM_GDSC>;
			resets = <&gcc GCC_USB30_PRIM_BCR>;
			interconnects = <&aggre1_noc MASTER_USB3 QCOM_ICC_TAG_ALWAYS
					 &mc_virt SLAVE_EBI_CH0 QCOM_ICC_TAG_ALWAYS>,
					<&gem_noc MASTER_AMPSS_M0 QCOM_ICC_TAG_ACTIVE_ONLY
					 &config_noc SLAVE_USB3 QCOM_ICC_TAG_ACTIVE_ONLY>;
			interconnect-names = "usb-ddr", "apps-usb";
			wakeup-source;

			/* No super-speed PHY described yet: run the controller HS-only */
			qcom,select-utmi-as-pipe-clk;

			usb_1_dwc3: usb@a600000 {
				compatible = "snps,dwc3";
				reg = <0x0 0x0a600000 0x0 0xcd00>;
				iommus = <&apps_smmu 0xe0 0x0>;
				interrupts = <GIC_SPI 240 IRQ_TYPE_LEVEL_HIGH>;
				phys = <&usb_1_hsphy>;
				phy-names = "usb2-phy";
				maximum-speed = "high-speed";
				snps,dis_u2_susphy_quirk;
				snps,dis_enblslpm_quirk;
				snps,dis-u1-entry-quirk;
				snps,dis-u2-entry-quirk;
			};
		};

		ufs_mem_hc: ufshc@1d84000 {
			compatible = "qcom,sm7250-ufshc", "qcom,ufshc",
				     "jedec,ufs-2.0";
			reg = <0x0 0x01d84000 0x0 0x3000>;
			interrupts = <GIC_SPI 265 IRQ_TYPE_LEVEL_HIGH>;
			phys = <&ufs_mem_phy>;
			phy-names = "ufsphy";
			lanes-per-direction = <2>;
			#reset-cells = <1>;
			resets = <&gcc GCC_UFS_PHY_BCR>;
			reset-names = "rst";
			power-domains = <&gcc UFS_PHY_GDSC>;

			/*
			 * The downstream ufshc node has no "iommus": its stream is
			 * left untranslated.
			 */

			pinctrl-names = "default",
					"dev-reset-assert",
					"dev-reset-deassert";
			pinctrl-0 = <&ufs_dev_reset_deassert>;
			pinctrl-1 = <&ufs_dev_reset_assert>;
			pinctrl-2 = <&ufs_dev_reset_deassert>;

			clock-names = "core_clk",
				      "bus_aggr_clk",
				      "iface_clk",
				      "core_clk_unipro",
				      "ref_clk",
				      "tx_lane0_sync_clk",
				      "rx_lane0_sync_clk",
				      "rx_lane1_sync_clk";
			clocks = <&gcc GCC_UFS_PHY_AXI_CLK>,
				 <&gcc GCC_AGGRE_UFS_PHY_AXI_CLK>,
				 <&gcc GCC_UFS_PHY_AHB_CLK>,
				 <&gcc GCC_UFS_PHY_UNIPRO_CORE_CLK>,
				 <&rpmhcc RPMH_CXO_CLK>,
				 <&gcc GCC_UFS_PHY_TX_SYMBOL_0_CLK>,
				 <&gcc GCC_UFS_PHY_RX_SYMBOL_0_CLK>,
				 <&gcc GCC_UFS_PHY_RX_SYMBOL_1_CLK>;

			operating-points-v2 = <&ufs_opp_table>;

			interconnects = <&aggre1_noc MASTER_UFS_MEM QCOM_ICC_TAG_ALWAYS
					 &mc_virt SLAVE_EBI_CH0 QCOM_ICC_TAG_ALWAYS>,
					<&gem_noc MASTER_AMPSS_M0 QCOM_ICC_TAG_ACTIVE_ONLY
					 &config_noc SLAVE_UFS_MEM_CFG QCOM_ICC_TAG_ACTIVE_ONLY>;
			interconnect-names = "ufs-ddr", "cpu-ufs";

			status = "disabled";

			ufs_opp_table: opp-table {
				compatible = "operating-points-v2";

				/* AXI and unipro clocks, from the downstream table */
				opp-50000000 {
					opp-hz = /bits/ 64 <50000000>,
						 /bits/ 64 <0>,
						 /bits/ 64 <0>,
						 /bits/ 64 <37500000>,
						 /bits/ 64 <0>,
						 /bits/ 64 <0>,
						 /bits/ 64 <0>,
						 /bits/ 64 <0>;
					required-opps = <&rpmhpd_opp_low_svs>;
				};

				opp-200000000 {
					opp-hz = /bits/ 64 <200000000>,
						 /bits/ 64 <0>,
						 /bits/ 64 <0>,
						 /bits/ 64 <150000000>,
						 /bits/ 64 <0>,
						 /bits/ 64 <0>,
						 /bits/ 64 <0>,
						 /bits/ 64 <0>;
					required-opps = <&rpmhpd_opp_nom>;
				};
			};
		};

		ufs_mem_phy: phy@1d87000 {
			compatible = "qcom,sm7250-qmp-ufs-phy";
			reg = <0x0 0x01d87000 0x0 0xe00>;

			clocks = <&rpmhcc RPMH_CXO_CLK>,
				 <&gcc GCC_UFS_PHY_PHY_AUX_CLK>,
				 <&gcc GCC_UFS_1X_CLKREF_CLK>;
			clock-names = "ref", "ref_aux", "qref";

			resets = <&ufs_mem_hc 0>;
			reset-names = "ufsphy";

			/*
			 * Nothing else votes for "qphy.lvl" once the modem is up,
			 * so the PHY holds it. The UFS GDSC is held by the host.
			 */
			power-domains = <&rpmhpd RPMHPD_QPHY>;

			#phy-cells = <0>;
			status = "disabled";
		};

		tlmm: pinctrl@f100000 {
			compatible = "qcom,sm7250-tlmm";
			reg = <0x0 0x0f100000 0x0 0x300000>,
			      <0x0 0x0f500000 0x0 0x300000>,
			      <0x0 0x0f900000 0x0 0x300000>;
			reg-names = "south", "west", "east";
			interrupts = <GIC_SPI 208 IRQ_TYPE_LEVEL_HIGH>;
			gpio-controller;
			#gpio-cells = <2>;
			interrupt-controller;
			#interrupt-cells = <2>;
			gpio-ranges = <&tlmm 0 0 146>;
			wakeup-parent = <&pdc>;

			ufs_dev_reset_assert: ufs-dev-reset-assert-state {
				pins = "ufs_reset";
				bias-pull-down;
				drive-strength = <8>;
				output-low;
			};

			ufs_dev_reset_deassert: ufs-dev-reset-deassert-state {
				pins = "ufs_reset";
				bias-pull-down;
				drive-strength = <8>;
				output-high;
			};
		};

		intc: interrupt-controller@17a00000 {
			compatible = "arm,gic-v3";
			reg = <0x0 0x17a00000 0x0 0x10000>,     /* GICD */
			      <0x0 0x17a60000 0x0 0x100000>;    /* GICR * 8 */
			#interrupt-cells = <3>;
			interrupt-controller;
			interrupts = <GIC_PPI 8 IRQ_TYPE_LEVEL_HIGH>;
		};

		watchdog@17c10000 {
			compatible = "qcom,apss-wdt-sm7250", "qcom,kpss-wdt";
			reg = <0x0 0x17c10000 0x0 0x1000>;
			clocks = <&sleep_clk>;
			interrupts = <GIC_SPI 0 IRQ_TYPE_EDGE_RISING>;
		};

		timer@17c20000 {
			compatible = "arm,armv7-timer-mem";
			#address-cells = <1>;
			#size-cells = <1>;
			ranges = <0 0 0 0x20000000>;
			reg = <0x0 0x17c20000 0x0 0x1000>;

			frame@17c21000 {
				frame-number = <0>;
				interrupts = <GIC_SPI 8 IRQ_TYPE_LEVEL_HIGH>,
					     <GIC_SPI 6 IRQ_TYPE_LEVEL_HIGH>;
				reg = <0x17c21000 0x1000>,
				      <0x17c22000 0x1000>;
			};

			frame@17c23000 {
				frame-number = <1>;
				interrupts = <GIC_SPI 9 IRQ_TYPE_LEVEL_HIGH>;
				reg = <0x17c23000 0x1000>;
				status = "disabled";
			};

			frame@17c25000 {
				frame-number = <2>;
				interrupts = <GIC_SPI 10 IRQ_TYPE_LEVEL_HIGH>;
				reg = <0x17c25000 0x1000>;
				status = "disabled";
			};

			frame@17c27000 {
				frame-number = <3>;
				interrupts = <GIC_SPI 11 IRQ_TYPE_LEVEL_HIGH>;
				reg = <0x17c27000 0x1000>;
				status = "disabled";
			};

			frame@17c29000 {
				frame-number = <4>;
				interrupts = <GIC_SPI 12 IRQ_TYPE_LEVEL_HIGH>;
				reg = <0x17c29000 0x1000>;
				status = "disabled";
			};

			frame@17c2b000 {
				frame-number = <5>;
				interrupts = <GIC_SPI 13 IRQ_TYPE_LEVEL_HIGH>;
				reg = <0x17c2b000 0x1000>;
				status = "disabled";
			};

			frame@17c2d000 {
				frame-number = <6>;
				interrupts = <GIC_SPI 14 IRQ_TYPE_LEVEL_HIGH>;
				reg = <0x17c2d000 0x1000>;
				status = "disabled";
			};
		};

		apps_rsc: rsc@18200000 {
			compatible = "qcom,rpmh-rsc";
			reg = <0x0 0x18200000 0x0 0x10000>,
			      <0x0 0x18210000 0x0 0x10000>,
			      <0x0 0x18220000 0x0 0x10000>;
			reg-names = "drv-0",
				    "drv-1",
				    "drv-2";
			interrupts = <GIC_SPI 3 IRQ_TYPE_LEVEL_HIGH>,
				     <GIC_SPI 4 IRQ_TYPE_LEVEL_HIGH>,
				     <GIC_SPI 5 IRQ_TYPE_LEVEL_HIGH>;
			label = "apps_rsc";
			qcom,tcs-offset = <0xd00>;
			qcom,drv-id = <2>;
			qcom,tcs-config = <ACTIVE_TCS  2>, <SLEEP_TCS   3>,
					  <WAKE_TCS    3>, <CONTROL_TCS 1>;
			power-domains = <&cluster_pd>;

			rpmhcc: clock-controller {
				compatible = "qcom,sm7250-rpmh-clk";
				#clock-cells = <1>;
				clock-names = "xo";
				clocks = <&xo_board>;
			};

			rpmhpd: power-controller {
				compatible = "qcom,sm7250-rpmhpd";
				#power-domain-cells = <1>;
				operating-points-v2 = <&rpmhpd_opp_table>;

				rpmhpd_opp_table: opp-table {
					compatible = "operating-points-v2";

					rpmhpd_opp_ret: opp1 {
						opp-level = <RPMH_REGULATOR_LEVEL_RETENTION>;
					};

					rpmhpd_opp_min_svs: opp2 {
						opp-level = <RPMH_REGULATOR_LEVEL_MIN_SVS>;
					};

					rpmhpd_opp_low_svs: opp3 {
						opp-level = <RPMH_REGULATOR_LEVEL_LOW_SVS>;
					};

					rpmhpd_opp_svs: opp4 {
						opp-level = <RPMH_REGULATOR_LEVEL_SVS>;
					};

					rpmhpd_opp_svs_l1: opp5 {
						opp-level = <RPMH_REGULATOR_LEVEL_SVS_L1>;
					};

					rpmhpd_opp_nom: opp6 {
						opp-level = <RPMH_REGULATOR_LEVEL_NOM>;
					};

					rpmhpd_opp_nom_l1: opp7 {
						opp-level = <RPMH_REGULATOR_LEVEL_NOM_L1>;
					};

					rpmhpd_opp_nom_l2: opp8 {
						opp-level = <RPMH_REGULATOR_LEVEL_NOM_L2>;
					};

					rpmhpd_opp_turbo: opp9 {
						opp-level = <RPMH_REGULATOR_LEVEL_TURBO>;
					};

					rpmhpd_opp_turbo_l1: opp10 {
						opp-level = <RPMH_REGULATOR_LEVEL_TURBO_L1>;
					};
				};
			};

			apps_bcm_voter: bcm-voter {
				compatible = "qcom,bcm-voter";
			};
		};

	};

	timer {
		compatible = "arm,armv8-timer";
		interrupts = <GIC_PPI 1 IRQ_TYPE_LEVEL_LOW>,
			     <GIC_PPI 2 IRQ_TYPE_LEVEL_LOW>,
			     <GIC_PPI 3 IRQ_TYPE_LEVEL_LOW>,
			     <GIC_PPI 0 IRQ_TYPE_LEVEL_LOW>;
	};
};
